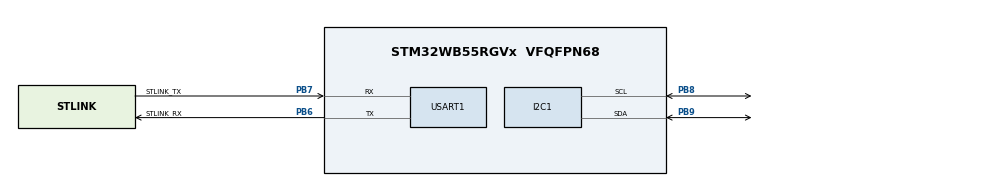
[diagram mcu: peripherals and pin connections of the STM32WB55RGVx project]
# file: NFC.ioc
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Dma.I2C1_RX.0.Direction=DMA_PERIPH_TO_MEMORY
Dma.I2C1_RX.0.EventEnable=DISABLE
Dma.I2C1_RX.0.Instance=DMA1_Channel1
Dma.I2C1_RX.0.MemDataAlignment=DMA_MDATAALIGN_BYTE
Dma.I2C1_RX.0.MemInc=DMA_MINC_ENABLE
Dma.I2C1_RX.0.Mode=DMA_NORMAL
Dma.I2C1_RX.0.PeriphDataAlignment=DMA_PDATAALIGN_BYTE
Dma.I2C1_RX.0.PeriphInc=DMA_PINC_DISABLE
Dma.I2C1_RX.0.Polarity=HAL_DMAMUX_REQ_GEN_RISING
Dma.I2C1_RX.0.Priority=DMA_PRIORITY_LOW
Dma.I2C1_RX.0.RequestNumber=1
Dma.I2C1_RX.0.SignalID=NONE
Dma.I2C1_RX.0.SyncEnable=DISABLE
Dma.I2C1_RX.0.SyncPolarity=HAL_DMAMUX_SYNC_NO_EVENT
Dma.I2C1_RX.0.SyncRequestNumber=1
Dma.I2C1_RX.0.SyncSignalID=NONE
Dma.Request0=I2C1_RX
FREERTOS.Tasks01=defaultTask,24,128,StartDefaultTask,Default,NULL,Dynamic,NULL,NULL
FREERTOS.configTOTAL_HEAP_SIZE=4096
FREERTOS.configUSE_NEWLIB_REENTRANT=1
I2C1.Timing=0x10B17DB5
Mcu.Family=STM32WB
Mcu.Name=STM32WB55RGVx
Mcu.Package=VFQFPN68
NVIC.DMA1_Channel1_IRQn=true\:5\:0\:false\:false\:true\:true\:false\:true\:true
NVIC.I2C1_ER_IRQn=true\:5\:0\:false\:false\:true\:true\:true\:true\:true
NVIC.I2C1_EV_IRQn=true\:5\:0\:false\:false\:true\:true\:true\:true\:true
NVIC.PriorityGroup=NVIC_PRIORITYGROUP_4
NVIC.TIM1_TRG_COM_TIM17_IRQn=true\:15\:0\:false\:false\:true\:false\:false\:true\:true
NVIC.TimeBase=TIM1_TRG_COM_TIM17_IRQn
NVIC.TimeBaseIP=TIM17
OSC_IN.GPIO_Label=RCC_OSC_IN
OSC_IN.Mode=HSE-External-Oscillator
OSC_IN.Signal=RCC_OSC_IN
OSC_OUT.GPIO_Label=RCC_OSC_OUT
OSC_OUT.Mode=HSE-External-Oscillator
OSC_OUT.Signal=RCC_OSC_OUT
PA11.GPIO_Label=USB_DM
PA11.Signal=USB_DM
PA12.GPIO_Label=USB_DP
PA12.Signal=USB_DP
PA13.GPIO_Label=JTMS
PA13.Mode=Serial_Wire
PA13.Signal=SYS_JTMS-SWDIO
PA14.GPIO_Label=JTCK
PA14.Mode=Serial_Wire
PA14.Signal=SYS_JTCK-SWCLK
PB3.GPIO_Label=JTDO
PB3.Signal=SYS_JTDO-SWO
PB6.GPIO_Label=STLINK_RX
PB6.Mode=Asynchronous
PB6.Signal=USART1_TX
PB7.GPIO_Label=STLINK_TX
PB7.Mode=Asynchronous
PB7.Signal=USART1_RX
PB8.Mode=I2C
PB8.Signal=I2C1_SCL
PB9.Mode=I2C
PB9.Signal=I2C1_SDA
PC13.GPIO_Label=SYS_WKUP2
PC13.Signal=SYS_WKUP2
PC14-OSC32_IN.GPIO_Label=RCC_OSC32_IN
PC14-OSC32_IN.Signal=RCC_OSC32_IN
PC15-OSC32_OUT.GPIO_Label=RCC_OSC32_OUT
PC15-OSC32_OUT.Signal=RCC_OSC32_OUT
ProjectManager.HeapSize=0x200
ProjectManager.StackSize=0x400
ProjectManager.TargetToolchain=STM32CubeIDE
RCC.ADCFreq_Value=16000000
RCC.AHB2CLKDivider=RCC_SYSCLK_DIV2
RCC.AHBFreq_Value=64000000
RCC.APB1Freq_Value=64000000
RCC.APB1TimFreq_Value=64000000
RCC.APB2Freq_Value=64000000
RCC.APB2TimFreq_Value=64000000
RCC.APB3Freq_Value=16000000
RCC.Cortex2_Div=SYSTICK_CLKSOURCE_HCLK_DIV8
RCC.CortexFreq_Value=64000000
RCC.HCLKFreq_Value=64000000
RCC.HSE_VALUE=32000000
RCC.HSI48_VALUE=48000000
RCC.HSI_VALUE=16000000
RCC.LSE_VALUE=32768
RCC.PLLN=32
RCC.SMPSCLockSelection=RCC_SMPSCLKSOURCE_HSI
RCC.SMPSCLockSelectionVirtual=RCC_SMPSCLKSOURCE_HSI
RCC.SMPSCLockSelectionVirtualVirtual=RCC_SMPSCLKSOURCE_HSI
RCC.SMPSDivider=1
RCC.SYSCLKFreq_VALUE=64000000
RCC.SYSCLKSource=RCC_SYSCLKSOURCE_PLLCLK
RCC.USBFreq_Value=16000000
RCC.VCOOutputFreq_Value=128000000
USART1.VirtualMode-Asynchronous=VM_ASYNC
VP_FREERTOS_VS_CMSIS_V2.Mode=CMSIS_V2
VP_MEMORYMAP_VS_MEMORYMAP.Mode=CurAppReg
VP_SYS_VS_tim17.Mode=TIM17
board=P-NUCLEO-WB55-NUCLEO

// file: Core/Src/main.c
/* USER CODE BEGIN Header */
/**
  ******************************************************************************
  * @file           : main.c
  * @brief          : Main program body
  ******************************************************************************
  * @attention
  *
  * Copyright (c) 2026 STMicroelectronics.
  * All rights reserved.
  *
  * This software is licensed under terms that can be found in the LICENSE file
  * in the root directory of this software component.
  * If no LICENSE file comes with this software, it is provided AS-IS.
  *
  ******************************************************************************
  */
/* USER CODE END Header */
#include "main.h"
#include "cmsis_os2.h"
#include "FreeRTOS.h"

/* USER CODE BEGIN Includes */
#include "nfc_app.h"
/* USER CODE END Includes */

I2C_HandleTypeDef hi2c1;
DMA_HandleTypeDef hdma_i2c1_rx;

UART_HandleTypeDef huart1;

/* Definitions for defaultTask */
osThreadId_t defaultTaskHandle;
const osThreadAttr_t defaultTask_attributes = {
  .name = "defaultTask",
  .priority = (osPriority_t) osPriorityNormal,
  .stack_size = 128 * 4
};

void SystemClock_Config(void);
void PeriphCommonClock_Config(void);
static void MX_GPIO_Init(void);
static void MX_DMA_Init(void);
static void MX_I2C1_Init(void);
static void MX_USART1_UART_Init(void);
void StartDefaultTask(void *argument);

int main(void)
{

  /* MCU Configuration--------------------------------------------------------*/

  /* Reset of all peripherals, Initializes the Flash interface and the Systick. */
  HAL_Init();

  /* Configure the system clock */
  SystemClock_Config();

  /* Configure the peripherals common clocks */
  PeriphCommonClock_Config();

  /* Initialize all configured peripherals */
  MX_GPIO_Init();
  MX_DMA_Init();
  MX_I2C1_Init();
  MX_USART1_UART_Init();

  /* Init scheduler */
  osKernelInitialize();

  /* Create the thread(s) */
  /* creation of defaultTask */
  defaultTaskHandle = osThreadNew(StartDefaultTask, NULL, &defaultTask_attributes);

  /* USER CODE BEGIN RTOS_THREADS */
  /* NTAG 5 application: NFC task (RF reader detection, I2C+DMA) and report task */
  NfcApp_Init(&hi2c1, &huart1);
  /* USER CODE END RTOS_THREADS */

  /* Start scheduler */
  osKernelStart();

  /* We should never get here as control is now taken by the scheduler */

  /* Infinite loop */
  while (1)
  {

  }
}

void SystemClock_Config(void)
{
  RCC_OscInitTypeDef RCC_OscInitStruct = {0};
  RCC_ClkInitTypeDef RCC_ClkInitStruct = {0};

  /** Configure the main internal regulator output voltage
  */
  __HAL_PWR_VOLTAGESCALING_CONFIG(PWR_REGULATOR_VOLTAGE_SCALE1);

  /** Initializes the RCC Oscillators according to the specified parameters
  * in the RCC_OscInitTypeDef structure.
  */
  RCC_OscInitStruct.OscillatorType = RCC_OSCILLATORTYPE_HSI|RCC_OSCILLATORTYPE_HSE
                              |RCC_OSCILLATORTYPE_MSI;
  RCC_OscInitStruct.HSEState = RCC_HSE_ON;
  RCC_OscInitStruct.HSIState = RCC_HSI_ON;
  RCC_OscInitStruct.MSIState = RCC_MSI_ON;
  RCC_OscInitStruct.HSICalibrationValue = RCC_HSICALIBRATION_DEFAULT;
  RCC_OscInitStruct.MSICalibrationValue = RCC_MSICALIBRATION_DEFAULT;
  RCC_OscInitStruct.MSIClockRange = RCC_MSIRANGE_6;
  RCC_OscInitStruct.PLL.PLLState = RCC_PLL_ON;
  RCC_OscInitStruct.PLL.PLLSource = RCC_PLLSOURCE_MSI;
  RCC_OscInitStruct.PLL.PLLM = RCC_PLLM_DIV1;
  RCC_OscInitStruct.PLL.PLLN = 32;
  RCC_OscInitStruct.PLL.PLLP = RCC_PLLP_DIV2;
  RCC_OscInitStruct.PLL.PLLR = RCC_PLLR_DIV2;
  RCC_OscInitStruct.PLL.PLLQ = RCC_PLLQ_DIV2;
  if (HAL_RCC_OscConfig(&RCC_OscInitStruct) != HAL_OK)
  {
    Error_Handler();
  }

  /** Configure the SYSCLKSource, HCLK, PCLK1 and PCLK2 clocks dividers
  */
  RCC_ClkInitStruct.ClockType = RCC_CLOCKTYPE_HCLK4|RCC_CLOCKTYPE_HCLK2
                              |RCC_CLOCKTYPE_HCLK|RCC_CLOCKTYPE_SYSCLK
                              |RCC_CLOCKTYPE_PCLK1|RCC_CLOCKTYPE_PCLK2;
  RCC_ClkInitStruct.SYSCLKSource = RCC_SYSCLKSOURCE_PLLCLK;
  RCC_ClkInitStruct.AHBCLKDivider = RCC_SYSCLK_DIV1;
  RCC_ClkInitStruct.APB1CLKDivider = RCC_HCLK_DIV1;
  RCC_ClkInitStruct.APB2CLKDivider = RCC_HCLK_DIV1;
  RCC_ClkInitStruct.AHBCLK2Divider = RCC_SYSCLK_DIV2;
  RCC_ClkInitStruct.AHBCLK4Divider = RCC_SYSCLK_DIV1;

  if (HAL_RCC_ClockConfig(&RCC_ClkInitStruct, FLASH_LATENCY_3) != HAL_OK)
  {
    Error_Handler();
  }
}

void PeriphCommonClock_Config(void)
{
  RCC_PeriphCLKInitTypeDef PeriphClkInitStruct = {0};

  /** Initializes the peripherals clock
  */
  PeriphClkInitStruct.PeriphClockSelection = RCC_PERIPHCLK_SMPS;
  PeriphClkInitStruct.SmpsClockSelection = RCC_SMPSCLKSOURCE_HSI;
  PeriphClkInitStruct.SmpsDivSelection = RCC_SMPSCLKDIV_RANGE0;

  if (HAL_RCCEx_PeriphCLKConfig(&PeriphClkInitStruct) != HAL_OK)
  {
    Error_Handler();
  }
}

static void MX_I2C1_Init(void)
{

  hi2c1.Instance = I2C1;
  hi2c1.Init.Timing = 0x10B17DB5;
  hi2c1.Init.OwnAddress1 = 0;
  hi2c1.Init.AddressingMode = I2C_ADDRESSINGMODE_7BIT;
  hi2c1.Init.DualAddressMode = I2C_DUALADDRESS_DISABLE;
  hi2c1.Init.OwnAddress2 = 0;
  hi2c1.Init.OwnAddress2Masks = I2C_OA2_NOMASK;
  hi2c1.Init.GeneralCallMode = I2C_GENERALCALL_DISABLE;
  hi2c1.Init.NoStretchMode = I2C_NOSTRETCH_DISABLE;
  if (HAL_I2C_Init(&hi2c1) != HAL_OK)
  {
    Error_Handler();
  }

  /** Configure Analogue filter
  */
  if (HAL_I2CEx_ConfigAnalogFilter(&hi2c1, I2C_ANALOGFILTER_ENABLE) != HAL_OK)
  {
    Error_Handler();
  }

  /** Configure Digital filter
  */
  if (HAL_I2CEx_ConfigDigitalFilter(&hi2c1, 0) != HAL_OK)
  {
    Error_Handler();
  }

}

static void MX_USART1_UART_Init(void)
{

  huart1.Instance = USART1;
  huart1.Init.BaudRate = 115200;
  huart1.Init.WordLength = UART_WORDLENGTH_8B;
  huart1.Init.StopBits = UART_STOPBITS_1;
  huart1.Init.Parity = UART_PARITY_NONE;
  huart1.Init.Mode = UART_MODE_TX_RX;
  huart1.Init.HwFlowCtl = UART_HWCONTROL_NONE;
  huart1.Init.OverSampling = UART_OVERSAMPLING_16;
  huart1.Init.OneBitSampling = UART_ONE_BIT_SAMPLE_DISABLE;
  huart1.Init.ClockPrescaler = UART_PRESCALER_DIV1;
  huart1.AdvancedInit.AdvFeatureInit = UART_ADVFEATURE_NO_INIT;
  if (HAL_UART_Init(&huart1) != HAL_OK)
  {
    Error_Handler();
  }
  if (HAL_UARTEx_SetTxFifoThreshold(&huart1, UART_TXFIFO_THRESHOLD_1_8) != HAL_OK)
  {
    Error_Handler();
  }
  if (HAL_UARTEx_SetRxFifoThreshold(&huart1, UART_RXFIFO_THRESHOLD_1_8) != HAL_OK)
  {
    Error_Handler();
  }
  if (HAL_UARTEx_DisableFifoMode(&huart1) != HAL_OK)
  {
    Error_Handler();
  }

}

static void MX_DMA_Init(void)
{

  /* DMA controller clock enable */
  __HAL_RCC_DMAMUX1_CLK_ENABLE();
  __HAL_RCC_DMA1_CLK_ENABLE();

  /* DMA interrupt init */
  /* DMA1_Channel1_IRQn interrupt configuration */
  HAL_NVIC_SetPriority(DMA1_Channel1_IRQn, 5, 0);
  HAL_NVIC_EnableIRQ(DMA1_Channel1_IRQn);

}

static void MX_GPIO_Init(void)
{
  GPIO_InitTypeDef GPIO_InitStruct = {0};

  /* GPIO Ports Clock Enable */
  __HAL_RCC_GPIOC_CLK_ENABLE();
  __HAL_RCC_GPIOB_CLK_ENABLE();
  __HAL_RCC_GPIOA_CLK_ENABLE();

  /*Configure GPIO pins : USB_DM_Pin USB_DP_Pin */
  GPIO_InitStruct.Pin = USB_DM_Pin|USB_DP_Pin;
  GPIO_InitStruct.Mode = GPIO_MODE_AF_PP;
  GPIO_InitStruct.Pull = GPIO_NOPULL;
  GPIO_InitStruct.Speed = GPIO_SPEED_FREQ_LOW;
  GPIO_InitStruct.Alternate = GPIO_AF10_USB;
  HAL_GPIO_Init(GPIOA, &GPIO_InitStruct);

}

void StartDefaultTask(void *argument)
{
  /* USER CODE BEGIN 5 */
  /* Infinite loop */
  for(;;)
  {
    osDelay(1000);
  }
  /* USER CODE END 5 */
}

void HAL_TIM_PeriodElapsedCallback(TIM_HandleTypeDef *htim)
{
  if (htim->Instance == TIM17)
  {
    HAL_IncTick();
  }
}

void Error_Handler(void)
{
  __disable_irq();
  while (1)
  {
  }
}
